AUTOSAR XML (schema 314)
package /VehicleProject
  system System: fibex-element=[CAN00, AFS_HS, AFS_HS__CAN00_Rx, AFS_HS__CAN00_Tx, AFS_Status_HS__CAN00, Antilock_Brake_and_TC_Status_HS__CAN00, Driven_Wheel_Grnd_Velocity_HS__CAN00, Driving_Mode_Control_HS__CAN00, DTC_Triggered_779__CAN00, NonDriven_Wheel_Grnd_Velocity_HS__CAN00, PPEI_Chassis_General_Status_1__CAN00, PPEI_Driven_Whl_Rotational_Stat__CAN00, PPEI_Engine_General_Status_1__CAN00, PPEI_Engine_General_Status_3__CAN00, PPEI_NonDrivn_Whl_Rotationl_Stat__CAN00, PPEI_Platform_General_Status__CAN00, PPEI_Trans_General_Status_2__CAN00, PPEI_VIN_Digits_10_to_17__CAN00, TsiCcpRx__CAN00, TsiCcpTx__CAN00, TsiDrvRxMsg__CAN00, TsiDrvTxMsg__CAN00, TsiTpRxMsg__CAN00, TsiTpTxMsg__CAN00, USDT_Req_to_AFS_HS__CAN00, USDT_Req_to_All_HS_ECUs__CAN00, USDT_Resp_From_AFS_HS__CAN00, UUDT_Resp_From_AFS_HS__CAN00, Vehicle_Odometer_HS__CAN00, VIN_Digits_2_to_9_HS__CAN00, Wheel_Pulses_HS__CAN00, AFS_Status_HS__CAN00, Antilock_Brake_and_TC_Status_HS__CAN00, Driven_Wheel_Grnd_Velocity_HS__CAN00, Driving_Mode_Control_HS__CAN00, DTC_Triggered_779__CAN00, NonDriven_Wheel_Grnd_Velocity_HS__CAN00, PPEI_Chassis_General_Status_1__CAN00, PPEI_Driven_Whl_Rotational_Stat__CAN00, PPEI_Engine_General_Status_1__CAN00, PPEI_Engine_General_Status_3__CAN00, PPEI_NonDrivn_Whl_Rotationl_Stat__CAN00, PPEI_Platform_General_Status__CAN00, PPEI_Trans_General_Status_2__CAN00, PPEI_VIN_Digits_10_to_17__CAN00, TsiCcpRx__CAN00, TsiCcpTx__CAN00, TsiDrvRxMsg__CAN00, TsiDrvTxMsg__CAN00, TsiTpRxMsg__CAN00, TsiTpTxMsg__CAN00, UUDT_Resp_From_AFS_HS__CAN00, Vehicle_Odometer_HS__CAN00, VIN_Digits_2_to_9_HS__CAN00, Wheel_Pulses_HS__CAN00, USDT_Req_to_AFS_HS__CAN00, USDT_Req_to_All_HS_ECUs__CAN00, USDT_Resp_From_AFS_HS__CAN00, USDT_Req_to_AFS_HS_Tp__CAN00, USDT_Req_to_All_HS_ECUs_Tp__CAN00, USDT_Resp_From_AFS_HS_Tp__CAN00, ABSAtv__PPEI_Chassis_General_Status_1__CAN00, ABSFld__PPEI_Chassis_General_Status_1__CAN00, AccActPos__PPEI_Engine_General_Status_1__CAN00, AccActPosV__PPEI_Engine_General_Status_1__CAN00, AFSIndOn__AFS_Status_HS__CAN00, AFSSysFail__AFS_Status_HS__CAN00, DrvMdCntrlState__Driving_Mode_Control_HS__CAN00, DTCI_CodeSupported_779__DTC_Triggered_779__CAN00, DTCI_CurrentStatus_779__DTC_Triggered_779__CAN00, DTCI_DTCFailType_779__DTC_Triggered_779__CAN00, DTCI_DTCFaultType_779__DTC_Triggered_779__CAN00, DTCI_DTCNumber_779__DTC_Triggered_779__CAN00, DTCI_DTCSource_779__DTC_Triggered_779__CAN00, DTCI_DTCTriggered_779__DTC_Triggered_779__CAN00, DTCI_HistStat_779__DTC_Triggered_779__CAN00, DTCI_TstFldCdClrdStat_779__DTC_Triggered_779__CAN00, DTCI_TstFldPwrUpSt_779__DTC_Triggered_779__CAN00, DTCI_TstNPsdCdClrdSt_779__DTC_Triggered_779__CAN00, DTCI_TstNPsdPwrUpSt_779__DTC_Triggered_779__CAN00, DTCI_WrnIndRqdSt_779__DTC_Triggered_779__CAN00, DTCIUnused1_779__DTC_Triggered_779__CAN00, DTCIUnused2_779__DTC_Triggered_779__CAN00, DTCIUnused3_779__DTC_Triggered_779__CAN00, DTCIUnused4_779__DTC_Triggered_779__CAN00, DTCIUnused5_779__DTC_Triggered_779__CAN00, DTCIUnused6_779__DTC_Triggered_779__CAN00, DTCIUnused7_779__DTC_Triggered_779__CAN00, EngRunAtv__PPEI_Engine_General_Status_1__CAN00, EngSpd__PPEI_Engine_General_Status_1__CAN00, FrStSysVeTpSpLimIndOn__AFS_Status_HS__CAN00, GenFld__PPEI_Engine_General_Status_3__CAN00, SG_DTCInfo_779__DTC_Triggered_779__CAN00, SG_WhlRotatStatLftDrvn__PPEI_Driven_Whl_Rotational_Stat__CAN00, SG_WhlRotatStatRtDrvn__PPEI_Driven_Whl_Rotational_Stat__CAN00, SG_WhlRotStatLftNDrvn__PPEI_NonDrivn_Whl_Rotationl_Stat__CAN00, SG_WhlRotStatRghtNDrvn__PPEI_NonDrivn_Whl_Rotationl_Stat__CAN00, SIRDpl__PPEI_Platform_General_Status__CAN00, StSysVehTopSpdLimReq__AFS_Status_HS__CAN00, SysBkUpPwrMd__PPEI_Platform_General_Status__CAN00, SysBkupPwrMdEn__PPEI_Platform_General_Status__CAN00, SysPwrMd__PPEI_Platform_General_Status__CAN00, TransEstGear__PPEI_Trans_General_Status_2__CAN00, TransEstGearV__PPEI_Trans_General_Status_2__CAN00, TrnsEngdState__PPEI_Trans_General_Status_2__CAN00, TrnsEngdStateV__PPEI_Trans_General_Status_2__CAN00, TrStLgMdAtv__PPEI_Platform_General_Status__CAN00, VehIdNmDig10_17__PPEI_VIN_Digits_10_to_17__CAN00, VehIdNmDig2_9__VIN_Digits_2_to_9_HS__CAN00, VehOdo__Vehicle_Odometer_HS__CAN00, VehOdoV__Vehicle_Odometer_HS__CAN00, VehStabEnhmntStat__Antilock_Brake_and_TC_Status_HS__CAN00, VhDynCntlSysSt__PPEI_Chassis_General_Status_1__CAN00, WhlGrndVlctyLftDrvn__Driven_Wheel_Grnd_Velocity_HS__CAN00, WhlGrndVlctyLftDrvnV__Driven_Wheel_Grnd_Velocity_HS__CAN00, WhlGrndVlctyLftNnDrvn__NonDriven_Wheel_Grnd_Velocity_HS__CAN00, WhlGrndVlctyLftNnDrvnV__NonDriven_Wheel_Grnd_Velocity_HS__CAN00, WhlGrndVlctyRtDrvn__Driven_Wheel_Grnd_Velocity_HS__CAN00, WhlGrndVlctyRtDrvnV__Driven_Wheel_Grnd_Velocity_HS__CAN00, WhlGrndVlctyRtNnDrvn__NonDriven_Wheel_Grnd_Velocity_HS__CAN00, WhlGrndVlctyRtNnDrvnV__NonDriven_Wheel_Grnd_Velocity_HS__CAN00, WhlPlsPerRevDrvn__Wheel_Pulses_HS__CAN00, WhlPlsPerRevNonDrvn__Wheel_Pulses_HS__CAN00, WRSLDSeqNum__PPEI_Driven_Whl_Rotational_Stat__CAN00, WRSLDWhlDistPlsCntr__PPEI_Driven_Whl_Rotational_Stat__CAN00, WRSLDWhlDisTpRC__PPEI_Driven_Whl_Rotational_Stat__CAN00, WRSLDWhlDistTmstm__PPEI_Driven_Whl_Rotational_Stat__CAN00, WRSLDWhlDistVal__PPEI_Driven_Whl_Rotational_Stat__CAN00, WRSLDWhlRotStatRst__PPEI_Driven_Whl_Rotational_Stat__CAN00, WRSLNDSeqNum__PPEI_NonDrivn_Whl_Rotationl_Stat__CAN00, WRSLNDWhlDistPCntr__PPEI_NonDrivn_Whl_Rotationl_Stat__CAN00, WRSLNDWhlDisTpRC__PPEI_NonDrivn_Whl_Rotationl_Stat__CAN00, WRSLNDWhlDistTstm__PPEI_NonDrivn_Whl_Rotationl_Stat__CAN00, WRSLNDWhlDistVal__PPEI_NonDrivn_Whl_Rotationl_Stat__CAN00, WRSLNDWhlRotStRst__PPEI_NonDrivn_Whl_Rotationl_Stat__CAN00, WRSRDSeqNum__PPEI_Driven_Whl_Rotational_Stat__CAN00, WRSRDWhlDistPlsCntr__PPEI_Driven_Whl_Rotational_Stat__CAN00, WRSRDWhlDisTpRC__PPEI_Driven_Whl_Rotational_Stat__CAN00, WRSRDWhlDistTmstm__PPEI_Driven_Whl_Rotational_Stat__CAN00, WRSRDWhlDistVal__PPEI_Driven_Whl_Rotational_Stat__CAN00, WRSRDWhlRotStatRst__PPEI_Driven_Whl_Rotational_Stat__CAN00, WRSRNDSeqNum__PPEI_NonDrivn_Whl_Rotationl_Stat__CAN00, WRSRNDWhlDistPCntr__PPEI_NonDrivn_Whl_Rotationl_Stat__CAN00, WRSRNDWhlDisTpRC__PPEI_NonDrivn_Whl_Rotationl_Stat__CAN00, WRSRNDWhlDistTstm__PPEI_NonDrivn_Whl_Rotationl_Stat__CAN00, WRSRNDWhlDistVal__PPEI_NonDrivn_Whl_Rotationl_Stat__CAN00, WRSRNDWhlRotStRst__PPEI_NonDrivn_Whl_Rotationl_Stat__CAN00]
package /Cluster
  can cluster CAN00: protocol-name=CAN, nm-lower-can-id=1536, nm-upper-can-id=1551  # gmHS | Primary High Speed GMLAN
    physical channel CHNL
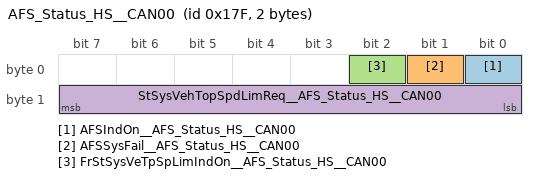
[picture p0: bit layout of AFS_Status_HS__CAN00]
      frame AFS_Status_HS__CAN00: id 0x17F, from AFS_HS, frame-length=2, can-addressing-mode=STANDARD
        pdu AFS_Status_HS__CAN00: length=16, cyclic-timing={repeating-time=0.1, starting-time=0}, minimum-delay=0, transmission-mode-false-timing=cyclic-timing={repeating-time=0.1, starting-time=0}
          signal AFSIndOn__AFS_Status_HS__CAN00: start 0, 1 bit, big-endian, data-type=DT_AFSIndOn, init-value=C_AFSIndOn, transfer-property=PENDING
          signal AFSSysFail__AFS_Status_HS__CAN00: start 1, 1 bit, big-endian, data-type=DT_AFSSysFail, init-value=C_AFSSysFail, transfer-property=PENDING
          signal FrStSysVeTpSpLimIndOn__AFS_Status_HS__CAN00: start 2, 1 bit, big-endian, data-type=DT_FrStSysVeTpSpLimIndOn, init-value=C_FrStSysVeTpSpLimIndOn, transfer-property=PENDING
          signal StSysVehTopSpdLimReq__AFS_Status_HS__CAN00: start 15, 8 bit, big-endian, data-type=DT_StSysVehTopSpdLimReq, init-value=C_StSysVehTopSpdLimReq, transfer-property=PENDING
      frame Antilock_Brake_and_TC_Status_HS__CAN00: id 0x17D, to AFS_HS, frame-length=6, can-addressing-mode=STANDARD
        pdu Antilock_Brake_and_TC_Status_HS__CAN00: length=48, cyclic-timing={repeating-time=0.1, starting-time=0}, minimum-delay=0, transmission-mode-false-timing=cyclic-timing={repeating-time=0.1, starting-time=0}
          signal VehStabEnhmntStat__Antilock_Brake_and_TC_Status_HS__CAN00: start 4, 3 bit, big-endian, data-type=DT_VehStabEnhmntStat, init-value=C_VehStabEnhmntStat, transfer-property=PENDING, to AFS_HS
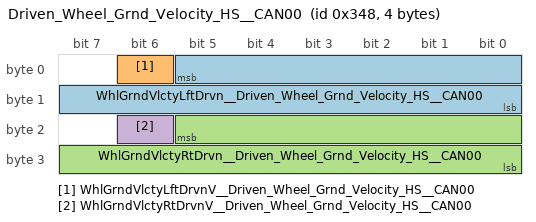
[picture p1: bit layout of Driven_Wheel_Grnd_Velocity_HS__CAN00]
      frame Driven_Wheel_Grnd_Velocity_HS__CAN00: id 0x348, to AFS_HS, frame-length=4, can-addressing-mode=STANDARD
        pdu Driven_Wheel_Grnd_Velocity_HS__CAN00: length=32, cyclic-timing={repeating-time=0.05, starting-time=0}, minimum-delay=0, transmission-mode-false-timing=cyclic-timing={repeating-time=0.05, starting-time=0}
          signal WhlGrndVlctyLftDrvn__Driven_Wheel_Grnd_Velocity_HS__CAN00: start 5, 14 bit, big-endian, data-type=DT_WhlGrndVlctyLftDrvn, init-value=C_WhlGrndVlctyLftDrvn, transfer-property=PENDING, to AFS_HS
          signal WhlGrndVlctyLftDrvnV__Driven_Wheel_Grnd_Velocity_HS__CAN00: start 6, 1 bit, big-endian, data-type=DT_WhlGrndVlctyLftDrvnV, init-value=C_WhlGrndVlctyLftDrvnV, transfer-property=PENDING, to AFS_HS
          signal WhlGrndVlctyRtDrvn__Driven_Wheel_Grnd_Velocity_HS__CAN00: start 21, 14 bit, big-endian, data-type=DT_WhlGrndVlctyRtDrvn, init-value=C_WhlGrndVlctyRtDrvn, transfer-property=PENDING, to AFS_HS
          signal WhlGrndVlctyRtDrvnV__Driven_Wheel_Grnd_Velocity_HS__CAN00: start 22, 1 bit, big-endian, data-type=DT_WhlGrndVlctyRtDrvnV, init-value=C_WhlGrndVlctyRtDrvnV, transfer-property=PENDING, to AFS_HS
      frame Driving_Mode_Control_HS__CAN00: id 0x232, to AFS_HS, frame-length=7, can-addressing-mode=STANDARD
        pdu Driving_Mode_Control_HS__CAN00: length=56, cyclic-timing={repeating-time=0.02, starting-time=0}, minimum-delay=0, transmission-mode-false-timing=cyclic-timing={repeating-time=0.02, starting-time=0}
          signal DrvMdCntrlState__Driving_Mode_Control_HS__CAN00: start 39, 8 bit, big-endian, data-type=DT_DrvMdCntrlState, init-value=C_DrvMdCntrlState, transfer-property=PENDING, to AFS_HS
      frame DTC_Triggered_779__CAN00: id 0x779, from AFS_HS, frame-length=7, can-addressing-mode=STANDARD
        pdu DTC_Triggered_779__CAN00: length=56, cyclic-timing={repeating-time=1, starting-time=0}, minimum-delay=0, transmission-mode-false-timing=cyclic-timing={repeating-time=1, starting-time=0}
          signal DTCI_DTCTriggered_779__DTC_Triggered_779__CAN00: start 0, 1 bit, big-endian, data-type=DT_DTCI_DTCTriggered_779, init-value=C_DTCI_DTCTriggered_779, transfer-property=PENDING
          signal DTCIUnused7_779__DTC_Triggered_779__CAN00: start 1, 1 bit, big-endian, data-type=DT_DTCIUnused7_779, init-value=C_DTCIUnused7_779, transfer-property=PENDING
          signal DTCIUnused6_779__DTC_Triggered_779__CAN00: start 2, 1 bit, big-endian, data-type=DT_DTCIUnused6_779, init-value=C_DTCIUnused6_779, transfer-property=PENDING
          signal DTCIUnused5_779__DTC_Triggered_779__CAN00: start 3, 1 bit, big-endian, data-type=DT_DTCIUnused5_779, init-value=C_DTCIUnused5_779, transfer-property=PENDING
          signal DTCIUnused4_779__DTC_Triggered_779__CAN00: start 4, 1 bit, big-endian, data-type=DT_DTCIUnused4_779, init-value=C_DTCIUnused4_779, transfer-property=PENDING
          signal DTCIUnused3_779__DTC_Triggered_779__CAN00: start 5, 1 bit, big-endian, data-type=DT_DTCIUnused3_779, init-value=C_DTCIUnused3_779, transfer-property=PENDING
          signal DTCIUnused2_779__DTC_Triggered_779__CAN00: start 6, 1 bit, big-endian, data-type=DT_DTCIUnused2_779, init-value=C_DTCIUnused2_779, transfer-property=PENDING
          signal DTCIUnused1_779__DTC_Triggered_779__CAN00: start 7, 1 bit, big-endian, data-type=DT_DTCIUnused1_779, init-value=C_DTCIUnused1_779, transfer-property=PENDING
          signal DTCI_DTCSource_779__DTC_Triggered_779__CAN00: start 15, 8 bit, big-endian, data-type=DT_DTCI_DTCSource_779, init-value=C_DTCI_DTCSource_779, transfer-property=PENDING  # This shall be equal to the Diagnostic Address of the transmittting device.
          signal DTCI_DTCNumber_779__DTC_Triggered_779__CAN00: start 23, 16 bit, big-endian, data-type=DT_DTCI_DTCNumber_779, init-value=C_DTCI_DTCNumber_779, transfer-property=PENDING
          signal DTCI_DTCFailType_779__DTC_Triggered_779__CAN00: start 39, 8 bit, big-endian, data-type=DT_DTCI_DTCFailType_779, init-value=C_DTCI_DTCFailType_779, transfer-property=PENDING  # Assigned per GMW3110, Appendix E
          signal DTCI_CodeSupported_779__DTC_Triggered_779__CAN00: start 40, 1 bit, big-endian, data-type=DT_DTCI_CodeSupported_779, init-value=C_DTCI_CodeSupported_779, transfer-property=PENDING
          signal DTCI_CurrentStatus_779__DTC_Triggered_779__CAN00: start 41, 1 bit, big-endian, data-type=DT_DTCI_CurrentStatus_779, init-value=C_DTCI_CurrentStatus_779, transfer-property=PENDING
          signal DTCI_TstNPsdCdClrdSt_779__DTC_Triggered_779__CAN00: start 42, 1 bit, big-endian, data-type=DT_DTCI_TstNPsdCdClrdSt_779, init-value=C_DTCI_TstNPsdCdClrdSt_779, transfer-property=PENDING
          signal DTCI_TstFldCdClrdStat_779__DTC_Triggered_779__CAN00: start 43, 1 bit, big-endian, data-type=DT_DTCI_TstFldCdClrdStat_779, init-value=C_DTCI_TstFldCdClrdStat_779, transfer-property=PENDING
          signal DTCI_HistStat_779__DTC_Triggered_779__CAN00: start 44, 1 bit, big-endian, data-type=DT_DTCI_HistStat_779, init-value=C_DTCI_HistStat_779, transfer-property=PENDING
          signal DTCI_TstNPsdPwrUpSt_779__DTC_Triggered_779__CAN00: start 45, 1 bit, big-endian, data-type=DT_DTCI_TstNPsdPwrUpSt_779, init-value=C_DTCI_TstNPsdPwrUpSt_779, transfer-property=PENDING
          signal DTCI_TstFldPwrUpSt_779__DTC_Triggered_779__CAN00: start 46, 1 bit, big-endian, data-type=DT_DTCI_TstFldPwrUpSt_779, init-value=C_DTCI_TstFldPwrUpSt_779, transfer-property=PENDING
          signal DTCI_WrnIndRqdSt_779__DTC_Triggered_779__CAN00: start 47, 1 bit, big-endian, data-type=DT_DTCI_WrnIndRqdSt_779, init-value=C_DTCI_WrnIndRqdSt_779, transfer-property=PENDING
          signal DTCI_DTCFaultType_779__DTC_Triggered_779__CAN00: start 55, 8 bit, big-endian, data-type=DT_DTCI_DTCFaultType_779, init-value=C_DTCI_DTCFaultType_779, transfer-property=PENDING  # Based on Powertrain definition. Not expected to be supported by all devices.
          signal SG_DTCInfo_779__DTC_Triggered_779__CAN00: start 7, big-endian, system-signal=[DTCI_CodeSupported_779, DTCI_CurrentStatus_779, DTCI_DTCFailType_779, DTCI_DTCFaultType_779, DTCI_DTCNumber_779, DTCI_DTCSource_779, DTCI_DTCTriggered_779, DTCI_HistStat_779, DTCI_TstFldCdClrdStat_779, DTCI_TstFldPwrUpSt_779, DTCI_TstNPsdCdClrdSt_779, DTCI_TstNPsdPwrUpSt_779, DTCI_WrnIndRqdSt_779, DTCIUnused1_779, DTCIUnused2_779, DTCIUnused3_779, DTCIUnused4_779, DTCIUnused5_779, DTCIUnused6_779, DTCIUnused7_779], transfer-property=PENDING
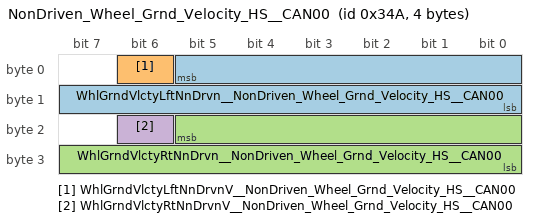
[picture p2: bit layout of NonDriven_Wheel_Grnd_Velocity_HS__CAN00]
      frame NonDriven_Wheel_Grnd_Velocity_HS__CAN00: id 0x34A, to AFS_HS, frame-length=4, can-addressing-mode=STANDARD
        pdu NonDriven_Wheel_Grnd_Velocity_HS__CAN00: length=32, cyclic-timing={repeating-time=0.05, starting-time=0}, minimum-delay=0, transmission-mode-false-timing=cyclic-timing={repeating-time=0.05, starting-time=0}
          signal WhlGrndVlctyLftNnDrvn__NonDriven_Wheel_Grnd_Velocity_HS__CAN00: start 5, 14 bit, big-endian, data-type=DT_WhlGrndVlctyLftNnDrvn, init-value=C_WhlGrndVlctyLftNnDrvn, transfer-property=PENDING, to AFS_HS
          signal WhlGrndVlctyLftNnDrvnV__NonDriven_Wheel_Grnd_Velocity_HS__CAN00: start 6, 1 bit, big-endian, data-type=DT_WhlGrndVlctyLftNnDrvnV, init-value=C_WhlGrndVlctyLftNnDrvnV, transfer-property=PENDING, to AFS_HS
          signal WhlGrndVlctyRtNnDrvn__NonDriven_Wheel_Grnd_Velocity_HS__CAN00: start 21, 14 bit, big-endian, data-type=DT_WhlGrndVlctyRtNnDrvn, init-value=C_WhlGrndVlctyRtNnDrvn, transfer-property=PENDING, to AFS_HS
          signal WhlGrndVlctyRtNnDrvnV__NonDriven_Wheel_Grnd_Velocity_HS__CAN00: start 22, 1 bit, big-endian, data-type=DT_WhlGrndVlctyRtNnDrvnV, init-value=C_WhlGrndVlctyRtNnDrvnV, transfer-property=PENDING, to AFS_HS
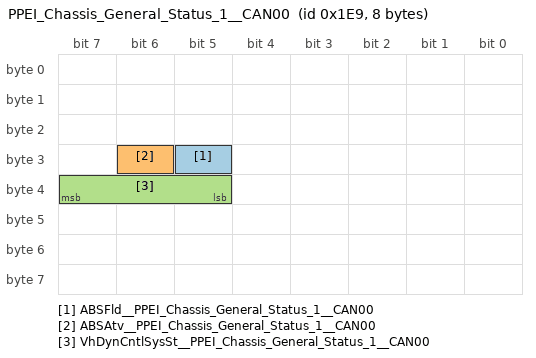
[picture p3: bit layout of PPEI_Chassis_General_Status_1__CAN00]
      frame PPEI_Chassis_General_Status_1__CAN00: id 0x1E9, to AFS_HS, frame-length=8, can-addressing-mode=STANDARD  # Changed for PPEI 3.6
        pdu PPEI_Chassis_General_Status_1__CAN00: length=64, cyclic-timing={repeating-time=0.02, starting-time=0}, minimum-delay=0, transmission-mode-false-timing=cyclic-timing={repeating-time=0.02, starting-time=0}
          signal ABSFld__PPEI_Chassis_General_Status_1__CAN00: start 29, 1 bit, big-endian, data-type=DT_ABSFld, init-value=C_ABSFld, transfer-property=PENDING, to AFS_HS
          signal ABSAtv__PPEI_Chassis_General_Status_1__CAN00: start 30, 1 bit, big-endian, data-type=DT_ABSAtv, init-value=C_ABSAtv, transfer-property=PENDING, to AFS_HS
          signal VhDynCntlSysSt__PPEI_Chassis_General_Status_1__CAN00: start 39, 3 bit, big-endian, data-type=DT_VhDynCntlSysSt, init-value=C_VhDynCntlSysSt, transfer-property=PENDING, to AFS_HS
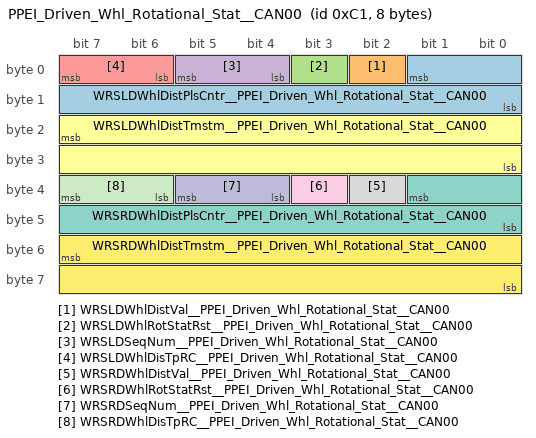
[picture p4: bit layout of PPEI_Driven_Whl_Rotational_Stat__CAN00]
      frame PPEI_Driven_Whl_Rotational_Stat__CAN00: id 0xC1, to AFS_HS, frame-length=8, can-addressing-mode=STANDARD
        pdu PPEI_Driven_Whl_Rotational_Stat__CAN00: length=64, cyclic-timing={repeating-time=0.01, starting-time=0}, minimum-delay=0, transmission-mode-false-timing=cyclic-timing={repeating-time=0.01, starting-time=0}
          signal WRSLDWhlDistPlsCntr__PPEI_Driven_Whl_Rotational_Stat__CAN00: start 1, 10 bit, big-endian, data-type=DT_WRSLDWhlDistPlsCntr, init-value=C_WRSLDWhlDistPlsCntr, transfer-property=PENDING, to AFS_HS
          signal WRSLDWhlDistVal__PPEI_Driven_Whl_Rotational_Stat__CAN00: start 2, 1 bit, big-endian, data-type=DT_WRSLDWhlDistVal, init-value=C_WRSLDWhlDistVal, transfer-property=PENDING, to AFS_HS
          signal WRSLDWhlRotStatRst__PPEI_Driven_Whl_Rotational_Stat__CAN00: start 3, 1 bit, big-endian, data-type=DT_WRSLDWhlRotStatRst, init-value=C_WRSLDWhlRotStatRst, transfer-property=PENDING, to AFS_HS
          signal WRSLDSeqNum__PPEI_Driven_Whl_Rotational_Stat__CAN00: start 5, 2 bit, big-endian, data-type=DT_WRSLDSeqNum, init-value=C_WRSLDSeqNum, transfer-property=PENDING, to AFS_HS
          signal WRSLDWhlDisTpRC__PPEI_Driven_Whl_Rotational_Stat__CAN00: start 7, 2 bit, big-endian, data-type=DT_WRSLDWhlDisTpRC, init-value=C_WRSLDWhlDisTpRC, transfer-property=PENDING, to AFS_HS
          signal WRSLDWhlDistTmstm__PPEI_Driven_Whl_Rotational_Stat__CAN00: start 23, 16 bit, big-endian, data-type=DT_WRSLDWhlDistTmstm, init-value=C_WRSLDWhlDistTmstm, transfer-property=PENDING, to AFS_HS
          signal WRSRDWhlDistPlsCntr__PPEI_Driven_Whl_Rotational_Stat__CAN00: start 33, 10 bit, big-endian, data-type=DT_WRSRDWhlDistPlsCntr, init-value=C_WRSRDWhlDistPlsCntr, transfer-property=PENDING, to AFS_HS
          signal WRSRDWhlDistVal__PPEI_Driven_Whl_Rotational_Stat__CAN00: start 34, 1 bit, big-endian, data-type=DT_WRSRDWhlDistVal, init-value=C_WRSRDWhlDistVal, transfer-property=PENDING, to AFS_HS
          signal WRSRDWhlRotStatRst__PPEI_Driven_Whl_Rotational_Stat__CAN00: start 35, 1 bit, big-endian, data-type=DT_WRSRDWhlRotStatRst, init-value=C_WRSRDWhlRotStatRst, transfer-property=PENDING, to AFS_HS
          signal WRSRDSeqNum__PPEI_Driven_Whl_Rotational_Stat__CAN00: start 37, 2 bit, big-endian, data-type=DT_WRSRDSeqNum, init-value=C_WRSRDSeqNum, transfer-property=PENDING, to AFS_HS
          signal WRSRDWhlDisTpRC__PPEI_Driven_Whl_Rotational_Stat__CAN00: start 39, 2 bit, big-endian, data-type=DT_WRSRDWhlDisTpRC, init-value=C_WRSRDWhlDisTpRC, transfer-property=PENDING, to AFS_HS
          signal WRSRDWhlDistTmstm__PPEI_Driven_Whl_Rotational_Stat__CAN00: start 55, 16 bit, big-endian, data-type=DT_WRSRDWhlDistTmstm, init-value=C_WRSRDWhlDistTmstm, transfer-property=PENDING, to AFS_HS
          signal SG_WhlRotatStatLftDrvn__PPEI_Driven_Whl_Rotational_Stat__CAN00: start 7, big-endian, system-signal=[WRSLDSeqNum, WRSLDWhlDistPlsCntr, WRSLDWhlDisTpRC, WRSLDWhlDistTmstm, WRSLDWhlDistVal, WRSLDWhlRotStatRst], transfer-property=PENDING
          signal SG_WhlRotatStatRtDrvn__PPEI_Driven_Whl_Rotational_Stat__CAN00: start 39, big-endian, system-signal=[WRSRDSeqNum, WRSRDWhlDistPlsCntr, WRSRDWhlDisTpRC, WRSRDWhlDistTmstm, WRSRDWhlDistVal, WRSRDWhlRotStatRst], transfer-property=PENDING
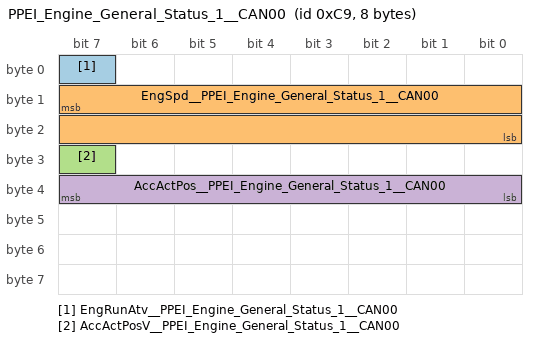
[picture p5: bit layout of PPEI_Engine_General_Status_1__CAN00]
      frame PPEI_Engine_General_Status_1__CAN00: id 0xC9, to AFS_HS, frame-length=8, can-addressing-mode=STANDARD  # Changed for PPEI 3.6
        pdu PPEI_Engine_General_Status_1__CAN00: length=64, cyclic-timing={repeating-time=0.012, starting-time=0}, minimum-delay=0, transmission-mode-false-timing=cyclic-timing={repeating-time=0.012, starting-time=0}
          signal EngRunAtv__PPEI_Engine_General_Status_1__CAN00: start 7, 1 bit, big-endian, data-type=DT_EngRunAtv, init-value=C_EngRunAtv, transfer-property=PENDING, to AFS_HS  # Indication from powertrain that the engine is running (Has RPM > 0)
          signal EngSpd__PPEI_Engine_General_Status_1__CAN00: start 15, 16 bit, big-endian, data-type=DT_EngSpd, init-value=C_EngSpd, transfer-property=PENDING, to AFS_HS
          signal AccActPosV__PPEI_Engine_General_Status_1__CAN00: start 31, 1 bit, big-endian, data-type=DT_AccActPosV, init-value=C_AccActPosV, transfer-property=PENDING, to AFS_HS
          signal AccActPos__PPEI_Engine_General_Status_1__CAN00: start 39, 8 bit, big-endian, data-type=DT_AccActPos, init-value=C_AccActPos, transfer-property=PENDING, to AFS_HS
      frame PPEI_Engine_General_Status_3__CAN00: id 0x3F9, to AFS_HS, frame-length=8, can-addressing-mode=STANDARD
        pdu PPEI_Engine_General_Status_3__CAN00: length=64, cyclic-timing={repeating-time=0.25, starting-time=0}, minimum-delay=0, transmission-mode-false-timing=cyclic-timing={repeating-time=0.25, starting-time=0}
          signal GenFld__PPEI_Engine_General_Status_3__CAN00: start 5, 1 bit, big-endian, data-type=DT_GenFld, init-value=C_GenFld, transfer-property=PENDING, to AFS_HS
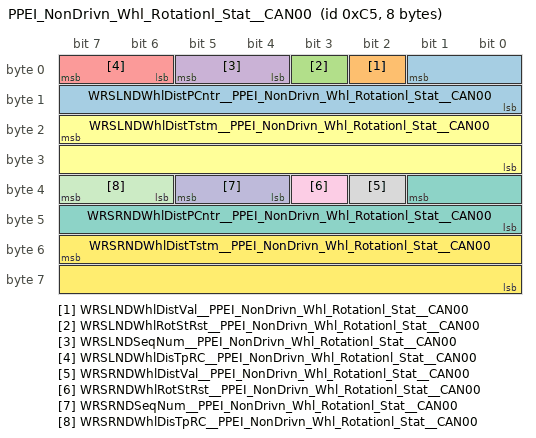
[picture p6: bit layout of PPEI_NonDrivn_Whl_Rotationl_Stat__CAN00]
      frame PPEI_NonDrivn_Whl_Rotationl_Stat__CAN00: id 0xC5, to AFS_HS, frame-length=8, can-addressing-mode=STANDARD
        pdu PPEI_NonDrivn_Whl_Rotationl_Stat__CAN00: length=64, cyclic-timing={repeating-time=0.01, starting-time=0}, minimum-delay=0, transmission-mode-false-timing=cyclic-timing={repeating-time=0.01, starting-time=0}
          signal WRSLNDWhlDistPCntr__PPEI_NonDrivn_Whl_Rotationl_Stat__CAN00: start 1, 10 bit, big-endian, data-type=DT_WRSLNDWhlDistPCntr, init-value=C_WRSLNDWhlDistPCntr, transfer-property=PENDING, to AFS_HS
          signal WRSLNDWhlDistVal__PPEI_NonDrivn_Whl_Rotationl_Stat__CAN00: start 2, 1 bit, big-endian, data-type=DT_WRSLNDWhlDistVal, init-value=C_WRSLNDWhlDistVal, transfer-property=PENDING, to AFS_HS
          signal WRSLNDWhlRotStRst__PPEI_NonDrivn_Whl_Rotationl_Stat__CAN00: start 3, 1 bit, big-endian, data-type=DT_WRSLNDWhlRotStRst, init-value=C_WRSLNDWhlRotStRst, transfer-property=PENDING, to AFS_HS
          signal WRSLNDSeqNum__PPEI_NonDrivn_Whl_Rotationl_Stat__CAN00: start 5, 2 bit, big-endian, data-type=DT_WRSLNDSeqNum, init-value=C_WRSLNDSeqNum, transfer-property=PENDING, to AFS_HS
          signal WRSLNDWhlDisTpRC__PPEI_NonDrivn_Whl_Rotationl_Stat__CAN00: start 7, 2 bit, big-endian, data-type=DT_WRSLNDWhlDisTpRC, init-value=C_WRSLNDWhlDisTpRC, transfer-property=PENDING, to AFS_HS
          signal WRSLNDWhlDistTstm__PPEI_NonDrivn_Whl_Rotationl_Stat__CAN00: start 23, 16 bit, big-endian, data-type=DT_WRSLNDWhlDistTstm, init-value=C_WRSLNDWhlDistTstm, transfer-property=PENDING, to AFS_HS
          signal WRSRNDWhlDistPCntr__PPEI_NonDrivn_Whl_Rotationl_Stat__CAN00: start 33, 10 bit, big-endian, data-type=DT_WRSRNDWhlDistPCntr, init-value=C_WRSRNDWhlDistPCntr, transfer-property=PENDING, to AFS_HS
          signal WRSRNDWhlDistVal__PPEI_NonDrivn_Whl_Rotationl_Stat__CAN00: start 34, 1 bit, big-endian, data-type=DT_WRSRNDWhlDistVal, init-value=C_WRSRNDWhlDistVal, transfer-property=PENDING, to AFS_HS
          signal WRSRNDWhlRotStRst__PPEI_NonDrivn_Whl_Rotationl_Stat__CAN00: start 35, 1 bit, big-endian, data-type=DT_WRSRNDWhlRotStRst, init-value=C_WRSRNDWhlRotStRst, transfer-property=PENDING, to AFS_HS
          signal WRSRNDSeqNum__PPEI_NonDrivn_Whl_Rotationl_Stat__CAN00: start 37, 2 bit, big-endian, data-type=DT_WRSRNDSeqNum, init-value=C_WRSRNDSeqNum, transfer-property=PENDING, to AFS_HS
          signal WRSRNDWhlDisTpRC__PPEI_NonDrivn_Whl_Rotationl_Stat__CAN00: start 39, 2 bit, big-endian, data-type=DT_WRSRNDWhlDisTpRC, init-value=C_WRSRNDWhlDisTpRC, transfer-property=PENDING, to AFS_HS
          signal WRSRNDWhlDistTstm__PPEI_NonDrivn_Whl_Rotationl_Stat__CAN00: start 55, 16 bit, big-endian, data-type=DT_WRSRNDWhlDistTstm, init-value=C_WRSRNDWhlDistTstm, transfer-property=PENDING, to AFS_HS
          signal SG_WhlRotStatLftNDrvn__PPEI_NonDrivn_Whl_Rotationl_Stat__CAN00: start 7, big-endian, system-signal=[WRSLNDSeqNum, WRSLNDWhlDistPCntr, WRSLNDWhlDisTpRC, WRSLNDWhlDistTstm, WRSLNDWhlDistVal, WRSLNDWhlRotStRst], transfer-property=PENDING
          signal SG_WhlRotStatRghtNDrvn__PPEI_NonDrivn_Whl_Rotationl_Stat__CAN00: start 39, big-endian, system-signal=[WRSRNDSeqNum, WRSRNDWhlDistPCntr, WRSRNDWhlDisTpRC, WRSRNDWhlDistTstm, WRSRNDWhlDistVal, WRSRNDWhlRotStRst], transfer-property=PENDING
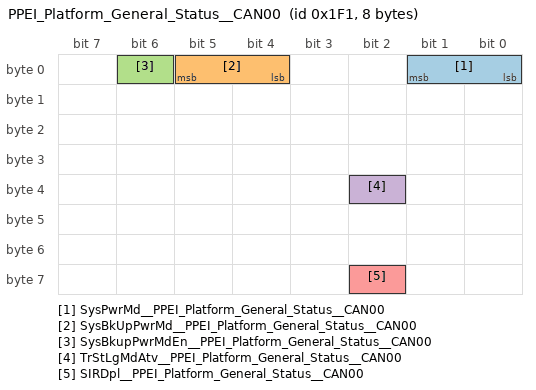
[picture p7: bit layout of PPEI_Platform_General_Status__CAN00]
      frame PPEI_Platform_General_Status__CAN00: id 0x1F1, to AFS_HS, frame-length=8, can-addressing-mode=STANDARD
        pdu PPEI_Platform_General_Status__CAN00: length=64, cyclic-timing={repeating-time=0.1, starting-time=0}, minimum-delay=0.03, transmission-mode-false-timing=cyclic-timing={repeating-time=0.1, starting-time=0}
          signal SysPwrMd__PPEI_Platform_General_Status__CAN00: start 1, 2 bit, big-endian, data-type=DT_SysPwrMd, init-value=C_SysPwrMd, transfer-property=PENDING, to AFS_HS
          signal SysBkUpPwrMd__PPEI_Platform_General_Status__CAN00: start 5, 2 bit, big-endian, data-type=DT_SysBkUpPwrMd, init-value=C_SysBkUpPwrMd, transfer-property=PENDING, to AFS_HS
          signal SysBkupPwrMdEn__PPEI_Platform_General_Status__CAN00: start 6, 1 bit, big-endian, data-type=DT_SysBkupPwrMdEn, init-value=C_SysBkupPwrMdEn, transfer-property=PENDING, to AFS_HS
          signal TrStLgMdAtv__PPEI_Platform_General_Status__CAN00: start 34, 1 bit, big-endian, data-type=DT_TrStLgMdAtv, init-value=C_TrStLgMdAtv, transfer-property=PENDING, to AFS_HS
          signal SIRDpl__PPEI_Platform_General_Status__CAN00: start 58, 1 bit, big-endian, data-type=DT_SIRDpl, init-value=C_SIRDpl, transfer-property=PENDING, to AFS_HS
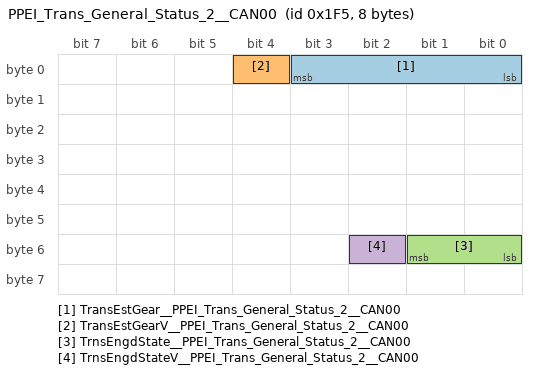
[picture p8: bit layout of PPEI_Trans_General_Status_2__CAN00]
      frame PPEI_Trans_General_Status_2__CAN00: id 0x1F5, to AFS_HS, frame-length=8, can-addressing-mode=STANDARD
        pdu PPEI_Trans_General_Status_2__CAN00: length=64, cyclic-timing={repeating-time=0.025, starting-time=0}, minimum-delay=0, transmission-mode-false-timing=cyclic-timing={repeating-time=0.025, starting-time=0}
          signal TransEstGear__PPEI_Trans_General_Status_2__CAN00: start 3, 4 bit, big-endian, data-type=DT_TransEstGear, init-value=C_TransEstGear, transfer-property=PENDING, to AFS_HS
          signal TransEstGearV__PPEI_Trans_General_Status_2__CAN00: start 4, 1 bit, big-endian, data-type=DT_TransEstGearV, init-value=C_TransEstGearV, transfer-property=PENDING, to AFS_HS
          signal TrnsEngdState__PPEI_Trans_General_Status_2__CAN00: start 49, 2 bit, big-endian, data-type=DT_TrnsEngdState, init-value=C_TrnsEngdState, transfer-property=PENDING, to AFS_HS
          signal TrnsEngdStateV__PPEI_Trans_General_Status_2__CAN00: start 50, 1 bit, big-endian, data-type=DT_TrnsEngdStateV, init-value=C_TrnsEngdStateV, transfer-property=PENDING, to AFS_HS
      frame PPEI_VIN_Digits_10_to_17__CAN00: id 0x4E1, to AFS_HS, frame-length=8, can-addressing-mode=STANDARD
        pdu PPEI_VIN_Digits_10_to_17__CAN00: length=64, cyclic-timing={repeating-time=1, starting-time=0}, minimum-delay=0, transmission-mode-false-timing=cyclic-timing={repeating-time=1, starting-time=0}
          signal VehIdNmDig10_17__PPEI_VIN_Digits_10_to_17__CAN00: start 7, 64 bit, big-endian, data-type=DT_VehIdNmDig10_17, init-value=C_VehIdNmDig10_17, transfer-property=PENDING, to AFS_HS  # Desc: 8 ASCII Characters
      frame TsiCcpRx__CAN00: id 0x791, to AFS_HS, frame-length=8, can-addressing-mode=STANDARD
        pdu TsiCcpRx__CAN00: length=64
      frame TsiCcpTx__CAN00: id 0x790, from AFS_HS, frame-length=8, can-addressing-mode=STANDARD
        pdu TsiCcpTx__CAN00: length=64
      frame TsiDrvRxMsg__CAN00: id 0x793, to AFS_HS, frame-length=8, can-addressing-mode=STANDARD
        pdu TsiDrvRxMsg__CAN00: length=64
      frame TsiDrvTxMsg__CAN00: id 0x792, from AFS_HS, frame-length=8, can-addressing-mode=STANDARD
        pdu TsiDrvTxMsg__CAN00: length=64
      frame TsiTpRxMsg__CAN00: id 0x795, to AFS_HS, frame-length=8, can-addressing-mode=STANDARD
        pdu TsiTpRxMsg__CAN00: length=64
      frame TsiTpTxMsg__CAN00: id 0x794, from AFS_HS, frame-length=8, can-addressing-mode=STANDARD
        pdu TsiTpTxMsg__CAN00: length=64
      frame USDT_Req_to_AFS_HS__CAN00: id 0x255, to AFS_HS, frame-length=8, can-addressing-mode=STANDARD
        n pdu USDT_Req_to_AFS_HS_Tp__CAN00: length=64
      frame USDT_Req_to_All_HS_ECUs__CAN00: id 0x101, to AFS_HS, frame-length=8, can-addressing-mode=STANDARD
        n pdu USDT_Req_to_All_HS_ECUs_Tp__CAN00: length=64
      frame USDT_Resp_From_AFS_HS__CAN00: id 0x655, from AFS_HS, frame-length=8, can-addressing-mode=STANDARD
        n pdu USDT_Resp_From_AFS_HS_Tp__CAN00: length=64
      frame UUDT_Resp_From_AFS_HS__CAN00: id 0x555, from AFS_HS, frame-length=8, can-addressing-mode=STANDARD
        pdu UUDT_Resp_From_AFS_HS__CAN00: length=64
      frame Vehicle_Odometer_HS__CAN00: id 0x120, to AFS_HS, frame-length=5, can-addressing-mode=STANDARD
        pdu Vehicle_Odometer_HS__CAN00: length=40, cyclic-timing={repeating-time=5, starting-time=0}, minimum-delay=0, transmission-mode-false-timing=cyclic-timing={repeating-time=5, starting-time=0}
          signal VehOdo__Vehicle_Odometer_HS__CAN00: start 7, 32 bit, big-endian, data-type=DT_VehOdo, init-value=C_VehOdo, transfer-property=PENDING, to AFS_HS
          signal VehOdoV__Vehicle_Odometer_HS__CAN00: start 32, 1 bit, big-endian, data-type=DT_VehOdoV, init-value=C_VehOdoV, transfer-property=PENDING, to AFS_HS
      frame VIN_Digits_2_to_9_HS__CAN00: id 0x514, to AFS_HS, frame-length=8, can-addressing-mode=STANDARD
        pdu VIN_Digits_2_to_9_HS__CAN00: length=64, cyclic-timing={repeating-time=1, starting-time=0}, minimum-delay=0, transmission-mode-false-timing=cyclic-timing={repeating-time=1, starting-time=0}
          signal VehIdNmDig2_9__VIN_Digits_2_to_9_HS__CAN00: start 7, 64 bit, big-endian, data-type=DT_VehIdNmDig2_9, init-value=C_VehIdNmDig2_9, transfer-property=PENDING, to AFS_HS  # Desc: 8 ASCII Characters
      frame Wheel_Pulses_HS__CAN00: id 0x500, to AFS_HS, frame-length=4, can-addressing-mode=STANDARD
        pdu Wheel_Pulses_HS__CAN00: length=32, cyclic-timing={repeating-time=1, starting-time=0}, minimum-delay=0, transmission-mode-false-timing=cyclic-timing={repeating-time=1, starting-time=0}
          signal WhlPlsPerRevDrvn__Wheel_Pulses_HS__CAN00: start 6, 7 bit, big-endian, data-type=DT_WhlPlsPerRevDrvn, init-value=C_WhlPlsPerRevDrvn, transfer-property=PENDING, to AFS_HS
          signal WhlPlsPerRevNonDrvn__Wheel_Pulses_HS__CAN00: start 14, 7 bit, big-endian, data-type=DT_WhlPlsPerRevNonDrvn, init-value=C_WhlPlsPerRevNonDrvn, transfer-property=PENDING, to AFS_HS
      pdu triggering PT_USDT_Req_to_AFS_HS: pdu=USDT_Req_to_AFS_HS__CAN00, to AFS_HS
      pdu triggering PT_USDT_Req_to_All_HS_ECUs: pdu=USDT_Req_to_All_HS_ECUs__CAN00, to AFS_HS
      pdu triggering PT_USDT_Resp_From_AFS_HS: pdu=USDT_Resp_From_AFS_HS__CAN00, from AFS_HS
      tp-channels:
        addressing-format=STANDARD, data-pdu=USDT_Req_to_All_HS_ECUs_Tp__CAN00, multicast-addressing=true, padding-activation=true, tp-sdu=USDT_Req_to_All_HS_ECUs__CAN00
        addressing-format=STANDARD, data-pdu=USDT_Req_to_All_HS_ECUs_Tp__CAN00, multicast-addressing=true, padding-activation=true, tp-sdu=USDT_Req_to_All_HS_ECUs__CAN00
        addressing-format=STANDARD, data-pdu=USDT_Resp_From_AFS_HS_Tp__CAN00, flow-control-pdu=USDT_Req_to_AFS_HS_Tp__CAN00, multicast-addressing=false, padding-activation=true, source=CN_CAN00, tp-sdu=USDT_Resp_From_AFS_HS__CAN00
        addressing-format=STANDARD, data-pdu=USDT_Resp_From_AFS_HS_Tp__CAN00, flow-control-pdu=USDT_Req_to_AFS_HS_Tp__CAN00, multicast-addressing=false, padding-activation=true, source=CN_CAN00, tp-sdu=USDT_Resp_From_AFS_HS__CAN00
        addressing-format=STANDARD, data-pdu=USDT_Req_to_AFS_HS_Tp__CAN00, flow-control-pdu=USDT_Resp_From_AFS_HS_Tp__CAN00, multicast-addressing=false, padding-activation=true, target=CN_CAN00, tp-sdu=USDT_Req_to_AFS_HS__CAN00
        addressing-format=STANDARD, data-pdu=USDT_Req_to_AFS_HS_Tp__CAN00, flow-control-pdu=USDT_Resp_From_AFS_HS_Tp__CAN00, multicast-addressing=false, padding-activation=true, target=CN_CAN00, tp-sdu=USDT_Req_to_AFS_HS__CAN00
package /ECU
  ecu instance AFS_HS: associated-i-pdu-group=[AFS_HS__CAN00_Rx, AFS_HS__CAN00_Tx], com-processing-period=0.001  # Active Front Steering
    can communication controller CT_CAN00
    communication connector CN_CAN00: channel=CHNL, comm-controller=CT_CAN00
package /IPDUGroup
  i pdu group AFS_HS__CAN00_Rx: communication-direction=IN, i-pdu=[Antilock_Brake_and_TC_Status_HS__CAN00, Driven_Wheel_Grnd_Velocity_HS__CAN00, Driving_Mode_Control_HS__CAN00, NonDriven_Wheel_Grnd_Velocity_HS__CAN00, PPEI_Chassis_General_Status_1__CAN00, PPEI_Driven_Whl_Rotational_Stat__CAN00, PPEI_Engine_General_Status_1__CAN00, PPEI_Engine_General_Status_3__CAN00, PPEI_NonDrivn_Whl_Rotationl_Stat__CAN00, PPEI_Platform_General_Status__CAN00, PPEI_Trans_General_Status_2__CAN00, PPEI_VIN_Digits_10_to_17__CAN00, Vehicle_Odometer_HS__CAN00, VIN_Digits_2_to_9_HS__CAN00, Wheel_Pulses_HS__CAN00]
  i pdu group AFS_HS__CAN00_Tx: communication-direction=OUT, i-pdu=[AFS_Status_HS__CAN00, DTC_Triggered_779__CAN00]
package /PDU
  dcm i pdu USDT_Req_to_AFS_HS__CAN00: length=64
  dcm i pdu USDT_Req_to_All_HS_ECUs__CAN00: length=64
  dcm i pdu USDT_Resp_From_AFS_HS__CAN00: length=64
package /DataType
  42 x boolean type:
    DT_ABSAtv: compu {0=Cx0_false, 1=Cx1_true}
    DT_ABSFld: compu {0=Cx0_false, 1=Cx1_true}
    DT_AccActPosV: compu {0=Cx0_Valid, 1=Cx1_Invalid}
    DT_AFSIndOn: compu {0=Cx0_false, 1=Cx1_true}
    DT_AFSSysFail: compu {0=Cx0_false, 1=Cx1_true}
    DT_DTCI_CodeSupported_779: compu {0=Cx0_false, 1=Cx1_true}
    DT_DTCI_CurrentStatus_779: compu {0=Cx0_false, 1=Cx1_true}
    DT_DTCI_DTCTriggered_779: compu {0=Cx0_false, 1=Cx1_true}
    DT_DTCI_HistStat_779: compu {0=Cx0_false, 1=Cx1_true}
    DT_DTCI_TstFldCdClrdStat_779: compu {0=Cx0_false, 1=Cx1_true}
    DT_DTCI_TstFldPwrUpSt_779: compu {0=Cx0_false, 1=Cx1_true}
    DT_DTCI_TstNPsdCdClrdSt_779: compu {0=Cx0_false, 1=Cx1_true}
    DT_DTCI_TstNPsdPwrUpSt_779: compu {0=Cx0_false, 1=Cx1_true}
    DT_DTCI_WrnIndRqdSt_779: compu {0=Cx0_false, 1=Cx1_true}
    DT_DTCIUnused{1..7}_779: compu {0=Cx0_false, 1=Cx1_true}
    DT_EngRunAtv: compu {0=Cx0_false, 1=Cx1_true}
    DT_FrStSysVeTpSpLimIndOn: compu {0=Cx0_false, 1=Cx1_true}
    DT_GenFld: compu {0=Cx0_false, 1=Cx1_true}
    DT_SIRDpl: compu {0=Cx0_false, 1=Cx1_true}
    DT_SysBkupPwrMdEn: compu {0=Cx0_false, 1=Cx1_true}
    DT_TransEstGearV: compu {0=Cx0_Valid, 1=Cx1_Invalid}
    DT_TrnsEngdStateV: compu {0=Cx0_Valid, 1=Cx1_Invalid}
    DT_TrStLgMdAtv: compu {0=Cx0_false, 1=Cx1_true}
    DT_VehOdoV: compu {0=Cx0_Valid, 1=Cx1_Invalid}
    DT_WhlGrndVlctyLftDrvnV: compu {0=Cx0_Valid, 1=Cx1_Invalid}
    DT_WhlGrndVlctyLftNnDrvnV: compu {0=Cx0_Valid, 1=Cx1_Invalid}
    DT_WhlGrndVlctyRtDrvnV: compu {0=Cx0_Valid, 1=Cx1_Invalid}
    DT_WhlGrndVlctyRtNnDrvnV: compu {0=Cx0_Valid, 1=Cx1_Invalid}
    DT_WRSLDWhlDistVal: compu {0=Cx0_Valid, 1=Cx1_Invalid}
    DT_WRSLDWhlRotStatRst: compu {0=Cx0_false, 1=Cx1_true}
    DT_WRSLNDWhlDistVal: compu {0=Cx0_Valid, 1=Cx1_Invalid}
    DT_WRSLNDWhlRotStRst: compu {0=Cx0_false, 1=Cx1_true}
    DT_WRSRDWhlDistVal: compu {0=Cx0_Valid, 1=Cx1_Invalid}
    DT_WRSRDWhlRotStatRst: compu {0=Cx0_false, 1=Cx1_true}
    DT_WRSRNDWhlDistVal: compu {0=Cx0_Valid, 1=Cx1_Invalid}
    DT_WRSRNDWhlRotStRst: compu {0=Cx0_false, 1=Cx1_true}
  37 x integer type, all with lower-limit=0:
    DT_AccActPos: compu {phys=raw*0.392157; unit %}, upper-limit=255
    DT_DrvMdCntrlState: upper-limit=255
    DT_DTCI_DTCFailType_779: upper-limit=255
    DT_DTCI_DTCFaultType_779: compu {0=Cx00_Not_Supported (Not Supported), 1=Cx01_Type_A (Type A), 2=Cx02_Type_B (Type B), 3=Cx03_Type_C (Type C)}, upper-limit=255
    DT_DTCI_DTCNumber_779: upper-limit=65535
    DT_DTCI_DTCSource_779: upper-limit=255
    DT_EngSpd: compu {phys=raw*0.25; unit rpm}, upper-limit=65535
    DT_StSysVehTopSpdLimReq: compu {phys=raw*2; unit km/h}, upper-limit=255
    DT_SysBkUpPwrMd: compu {0=Cx0_Off, 1=Cx1_Accessory, 2=Cx2_Run, 3=Cx3_Crank_Request (Crank Request)}, upper-limit=3
    DT_SysPwrMd: compu {0=Cx0_Off, 1=Cx1_Accessory, 2=Cx2_Run, 3=Cx3_Crank_Request (Crank Request)}, upper-limit=3
    DT_TransEstGear: compu {0=Cx0_Not_Supported (Not Supported), 1=Cx1_First_Gear (First Gear), 2=Cx2_Second_Gear (Second Gear), 3=Cx3_Third_Gear (Third Gear), 4=Cx4_Fourth_Gear (Fourth Gear), 5=Cx5_Fifth_Gear (Fifth Gear), 6=Cx6_Sixth_Gear (Sixth Gear), 7=Cx7_Seventh_Gear (Seventh Gear), 8=Cx8_Eighth_Gear (Eighth Gear), 12=CxC_CVT_Forward_Gear (CVT Forward Gear), 13=CxD_Neutral_Gear (Neutral Gear), 14=CxE_Reverse_Gear (Reverse Gear), 15=CxF_Park_Gear (Park Gear)}, upper-limit=15
    DT_TrnsEngdState: compu {0=Cx0_Transmission_Not_Engaged (Transmission Not Engaged), 1=Cx1_Transmission_Engaged_in_Forward (Transmission Engaged in Forward), 2=Cx2_Transmission_Engaged_in_Reverse (Transmission Engaged in Reverse), 3=Cx3_Operating_State_Not_Reached (Operating State Not Reached)}, upper-limit=3
    DT_VehOdo: compu {phys=raw/64; unit km}, upper-limit=4294967295
    DT_VehStabEnhmntStat: compu {0=Cx0_Inactive, 1=Cx1_Active, 2=Cx2_Fault, 3=Cx3_Warming_Up (Warming Up), 4=Cx4_Not_Ready (Not Ready)}, upper-limit=7
    DT_VhDynCntlSysSt: compu {0=Cx0_Normal_Operation (Normal Operation), 1=Cx1_Reduced_Function (Reduced Function), 2=Cx2_Temporarily_Inhibited (Temporarily Inhibited), 3=Cx3_Permanently_Failed (Permanently Failed), 4=Cx4_Warming_Up (Warming Up), 5=Cx5_Calibrating, 6=Cx6_Enhanced_Operation (Enhanced Operation), 7=Cx7_Driver_Disabled (Driver Disabled)}, upper-limit=7
    DT_WhlGrndVlctyLftDrvn: compu {phys=raw/32; unit km / h}, upper-limit=16383
    DT_WhlGrndVlctyLftNnDrvn: compu {phys=raw/32; unit km / h}, upper-limit=16383
    DT_WhlGrndVlctyRtDrvn: compu {phys=raw/32; unit km / h}, upper-limit=16383
    DT_WhlGrndVlctyRtNnDrvn: compu {phys=raw/32; unit km / h}, upper-limit=16383
    DT_WhlPlsPerRevDrvn: upper-limit=127
    DT_WhlPlsPerRevNonDrvn: upper-limit=127
    DT_WRSLDSeqNum: compu {; unit counts}, upper-limit=3
    DT_WRSLDWhlDistPlsCntr: compu {; unit counts}, upper-limit=1023
    DT_WRSLDWhlDisTpRC: compu {; unit counts}, upper-limit=3
    DT_WRSLDWhlDistTmstm: compu {; unit counts}, upper-limit=65535
    DT_WRSLNDSeqNum: compu {; unit counts}, upper-limit=3
    DT_WRSLNDWhlDistPCntr: compu {; unit counts}, upper-limit=1023
    DT_WRSLNDWhlDisTpRC: compu {; unit counts}, upper-limit=3
    DT_WRSLNDWhlDistTstm: compu {; unit counts}, upper-limit=65535
    DT_WRSRDSeqNum: compu {; unit counts}, upper-limit=3
    DT_WRSRDWhlDistPlsCntr: compu {; unit counts}, upper-limit=1023
    DT_WRSRDWhlDisTpRC: compu {; unit counts}, upper-limit=3
    DT_WRSRDWhlDistTmstm: compu {; unit counts}, upper-limit=65535
    DT_WRSRNDSeqNum: compu {; unit counts}, upper-limit=3
    DT_WRSRNDWhlDistPCntr: compu {; unit counts}, upper-limit=1023
    DT_WRSRNDWhlDisTpRC: compu {; unit counts}, upper-limit=3
    DT_WRSRNDWhlDistTstm: compu {; unit counts}, upper-limit=65535
  string type DT_VehIdNmDig10_17: encoding=ISO-8859-1, max-number-of-chars=8
  string type DT_VehIdNmDig2_9: encoding=ISO-8859-1, max-number-of-chars=8
package /DataType/Unit
  6 x unit:
    U_counts: display-name=counts
    U_km: display-name=km
    U_km___h: display-name=km / h
    U_km_h: display-name=km/h
    U_p: display-name=%
    U_rpm: display-name=rpm
package /Constant
  81 x constant specification:
    C_ABSAtv
      value:
        boolean literal C_ABSAtv: type=DT_ABSAtv, value=false
    C_ABSFld
      value:
        boolean literal C_ABSFld: type=DT_ABSFld, value=false
    C_AccActPosV
      value:
        boolean literal C_AccActPosV: type=DT_AccActPosV, value=false
    C_AFSIndOn
      value:
        boolean literal C_AFSIndOn: type=DT_AFSIndOn, value=false
    C_AFSSysFail
      value:
        boolean literal C_AFSSysFail: type=DT_AFSSysFail, value=false
    C_DTCI_CodeSupported_779
      value:
        boolean literal C_DTCI_CodeSupported_779: type=DT_DTCI_CodeSupported_779, value=false
    C_DTCI_CurrentStatus_779
      value:
        boolean literal C_DTCI_CurrentStatus_779: type=DT_DTCI_CurrentStatus_779, value=false
    C_DTCI_DTCTriggered_779
      value:
        boolean literal C_DTCI_DTCTriggered_779: type=DT_DTCI_DTCTriggered_779, value=false
    C_DTCI_HistStat_779
      value:
        boolean literal C_DTCI_HistStat_779: type=DT_DTCI_HistStat_779, value=false
    C_DTCI_TstFldCdClrdStat_779
      value:
        boolean literal C_DTCI_TstFldCdClrdStat_779: type=DT_DTCI_TstFldCdClrdStat_779, value=false
    C_DTCI_TstFldPwrUpSt_779
      value:
        boolean literal C_DTCI_TstFldPwrUpSt_779: type=DT_DTCI_TstFldPwrUpSt_779, value=false
    C_DTCI_TstNPsdCdClrdSt_779
      value:
        boolean literal C_DTCI_TstNPsdCdClrdSt_779: type=DT_DTCI_TstNPsdCdClrdSt_779, value=false
    C_DTCI_TstNPsdPwrUpSt_779
      value:
        boolean literal C_DTCI_TstNPsdPwrUpSt_779: type=DT_DTCI_TstNPsdPwrUpSt_779, value=false
    C_DTCI_WrnIndRqdSt_779
      value:
        boolean literal C_DTCI_WrnIndRqdSt_779: type=DT_DTCI_WrnIndRqdSt_779, value=false
    C_DTCIUnused1_779
      value:
        boolean literal C_DTCIUnused1_779: type=DT_DTCIUnused1_779, value=false
    C_DTCIUnused2_779
      value:
        boolean literal C_DTCIUnused2_779: type=DT_DTCIUnused2_779, value=false
    C_DTCIUnused3_779
      value:
        boolean literal C_DTCIUnused3_779: type=DT_DTCIUnused3_779, value=false
    C_DTCIUnused4_779
      value:
        boolean literal C_DTCIUnused4_779: type=DT_DTCIUnused4_779, value=false
    C_DTCIUnused5_779
      value:
        boolean literal C_DTCIUnused5_779: type=DT_DTCIUnused5_779, value=false
    C_DTCIUnused6_779
      value:
        boolean literal C_DTCIUnused6_779: type=DT_DTCIUnused6_779, value=false
    C_DTCIUnused7_779
      value:
        boolean literal C_DTCIUnused7_779: type=DT_DTCIUnused7_779, value=false
    C_EngRunAtv
      value:
        boolean literal C_EngRunAtv: type=DT_EngRunAtv, value=false
    C_FrStSysVeTpSpLimIndOn
      value:
        boolean literal C_FrStSysVeTpSpLimIndOn: type=DT_FrStSysVeTpSpLimIndOn, value=false
    C_GenFld
      value:
        boolean literal C_GenFld: type=DT_GenFld, value=false
    C_SIRDpl
      value:
        boolean literal C_SIRDpl: type=DT_SIRDpl, value=false
    C_SysBkupPwrMdEn
      value:
        boolean literal C_SysBkupPwrMdEn: type=DT_SysBkupPwrMdEn, value=false
    C_TransEstGearV
      value:
        boolean literal C_TransEstGearV: type=DT_TransEstGearV, value=false
    C_TrnsEngdStateV
      value:
        boolean literal C_TrnsEngdStateV: type=DT_TrnsEngdStateV, value=false
    C_TrStLgMdAtv
      value:
        boolean literal C_TrStLgMdAtv: type=DT_TrStLgMdAtv, value=false
    C_VehOdoV
      value:
        boolean literal C_VehOdoV: type=DT_VehOdoV, value=false
    C_WhlGrndVlctyLftDrvnV
      value:
        boolean literal C_WhlGrndVlctyLftDrvnV: type=DT_WhlGrndVlctyLftDrvnV, value=false
    C_WhlGrndVlctyLftNnDrvnV
      value:
        boolean literal C_WhlGrndVlctyLftNnDrvnV: type=DT_WhlGrndVlctyLftNnDrvnV, value=false
    C_WhlGrndVlctyRtDrvnV
      value:
        boolean literal C_WhlGrndVlctyRtDrvnV: type=DT_WhlGrndVlctyRtDrvnV, value=false
    C_WhlGrndVlctyRtNnDrvnV
      value:
        boolean literal C_WhlGrndVlctyRtNnDrvnV: type=DT_WhlGrndVlctyRtNnDrvnV, value=false
    C_WRSLDWhlDistVal
      value:
        boolean literal C_WRSLDWhlDistVal: type=DT_WRSLDWhlDistVal, value=false
    C_WRSLDWhlRotStatRst
      value:
        boolean literal C_WRSLDWhlRotStatRst: type=DT_WRSLDWhlRotStatRst, value=false
    C_WRSLNDWhlDistVal
      value:
        boolean literal C_WRSLNDWhlDistVal: type=DT_WRSLNDWhlDistVal, value=false
    C_WRSLNDWhlRotStRst
      value:
        boolean literal C_WRSLNDWhlRotStRst: type=DT_WRSLNDWhlRotStRst, value=false
    C_WRSRDWhlDistVal
      value:
        boolean literal C_WRSRDWhlDistVal: type=DT_WRSRDWhlDistVal, value=false
    C_WRSRDWhlRotStatRst
      value:
        boolean literal C_WRSRDWhlRotStatRst: type=DT_WRSRDWhlRotStatRst, value=false
    C_WRSRNDWhlDistVal
      value:
        boolean literal C_WRSRNDWhlDistVal: type=DT_WRSRNDWhlDistVal, value=false
    C_WRSRNDWhlRotStRst
      value:
        boolean literal C_WRSRNDWhlRotStRst: type=DT_WRSRNDWhlRotStRst, value=false
    C_AccActPos
      value:
        integer literal C_AccActPos: type=DT_AccActPos, value=0
    C_DrvMdCntrlState
      value:
        integer literal C_DrvMdCntrlState: type=DT_DrvMdCntrlState, value=0
    C_DTCI_DTCFailType_779
      value:
        integer literal C_DTCI_DTCFailType_779: type=DT_DTCI_DTCFailType_779, value=0
    C_DTCI_DTCFaultType_779
      value:
        integer literal C_DTCI_DTCFaultType_779: type=DT_DTCI_DTCFaultType_779, value=0
    C_DTCI_DTCNumber_779
      value:
        integer literal C_DTCI_DTCNumber_779: type=DT_DTCI_DTCNumber_779, value=0
    C_DTCI_DTCSource_779
      value:
        integer literal C_DTCI_DTCSource_779: type=DT_DTCI_DTCSource_779, value=0
    C_EngSpd
      value:
        integer literal C_EngSpd: type=DT_EngSpd, value=0
    C_StSysVehTopSpdLimReq
      value:
        integer literal C_StSysVehTopSpdLimReq: type=DT_StSysVehTopSpdLimReq, value=0
    C_SysBkUpPwrMd
      value:
        integer literal C_SysBkUpPwrMd: type=DT_SysBkUpPwrMd, value=0
    C_SysPwrMd
      value:
        integer literal C_SysPwrMd: type=DT_SysPwrMd, value=0
    C_TransEstGear
      value:
        integer literal C_TransEstGear: type=DT_TransEstGear, value=15
    C_TrnsEngdState
      value:
        integer literal C_TrnsEngdState: type=DT_TrnsEngdState, value=0
    C_VehOdo
      value:
        integer literal C_VehOdo: type=DT_VehOdo, value=0
    C_VehStabEnhmntStat
      value:
        integer literal C_VehStabEnhmntStat: type=DT_VehStabEnhmntStat, value=0
    C_VhDynCntlSysSt
      value:
        integer literal C_VhDynCntlSysSt: type=DT_VhDynCntlSysSt, value=0
    C_WhlGrndVlctyLftDrvn
      value:
        integer literal C_WhlGrndVlctyLftDrvn: type=DT_WhlGrndVlctyLftDrvn, value=0
    C_WhlGrndVlctyLftNnDrvn
      value:
        integer literal C_WhlGrndVlctyLftNnDrvn: type=DT_WhlGrndVlctyLftNnDrvn, value=0
    C_WhlGrndVlctyRtDrvn
      value:
        integer literal C_WhlGrndVlctyRtDrvn: type=DT_WhlGrndVlctyRtDrvn, value=0
    C_WhlGrndVlctyRtNnDrvn
      value:
        integer literal C_WhlGrndVlctyRtNnDrvn: type=DT_WhlGrndVlctyRtNnDrvn, value=0
    C_WhlPlsPerRevDrvn
      value:
        integer literal C_WhlPlsPerRevDrvn: type=DT_WhlPlsPerRevDrvn, value=0
    C_WhlPlsPerRevNonDrvn
      value:
        integer literal C_WhlPlsPerRevNonDrvn: type=DT_WhlPlsPerRevNonDrvn, value=0
    C_WRSLDSeqNum
      value:
        integer literal C_WRSLDSeqNum: type=DT_WRSLDSeqNum, value=0
    C_WRSLDWhlDistPlsCntr
      value:
        integer literal C_WRSLDWhlDistPlsCntr: type=DT_WRSLDWhlDistPlsCntr, value=0
    C_WRSLDWhlDisTpRC
      value:
        integer literal C_WRSLDWhlDisTpRC: type=DT_WRSLDWhlDisTpRC, value=0
    C_WRSLDWhlDistTmstm
      value:
        integer literal C_WRSLDWhlDistTmstm: type=DT_WRSLDWhlDistTmstm, value=0
    C_WRSLNDSeqNum
      value:
        integer literal C_WRSLNDSeqNum: type=DT_WRSLNDSeqNum, value=0
    C_WRSLNDWhlDistPCntr
      value:
        integer literal C_WRSLNDWhlDistPCntr: type=DT_WRSLNDWhlDistPCntr, value=0
    C_WRSLNDWhlDisTpRC
      value:
        integer literal C_WRSLNDWhlDisTpRC: type=DT_WRSLNDWhlDisTpRC, value=0
    C_WRSLNDWhlDistTstm
      value:
        integer literal C_WRSLNDWhlDistTstm: type=DT_WRSLNDWhlDistTstm, value=0
    C_WRSRDSeqNum
      value:
        integer literal C_WRSRDSeqNum: type=DT_WRSRDSeqNum, value=0
    C_WRSRDWhlDistPlsCntr
      value:
        integer literal C_WRSRDWhlDistPlsCntr: type=DT_WRSRDWhlDistPlsCntr, value=0
    C_WRSRDWhlDisTpRC
      value:
        integer literal C_WRSRDWhlDisTpRC: type=DT_WRSRDWhlDisTpRC, value=0
    C_WRSRDWhlDistTmstm
      value:
        integer literal C_WRSRDWhlDistTmstm: type=DT_WRSRDWhlDistTmstm, value=0
    C_WRSRNDSeqNum
      value:
        integer literal C_WRSRNDSeqNum: type=DT_WRSRNDSeqNum, value=0
    C_WRSRNDWhlDistPCntr
      value:
        integer literal C_WRSRNDWhlDistPCntr: type=DT_WRSRNDWhlDistPCntr, value=0
    C_WRSRNDWhlDisTpRC
      value:
        integer literal C_WRSRNDWhlDisTpRC: type=DT_WRSRNDWhlDisTpRC, value=0
    C_WRSRNDWhlDistTstm
      value:
        integer literal C_WRSRNDWhlDistTstm: type=DT_WRSRNDWhlDistTstm, value=0
    C_VehIdNmDig10_17
      value:
        string literal C_VehIdNmDig10_17: type=DT_VehIdNmDig10_17
    C_VehIdNmDig2_9
      value:
        string literal C_VehIdNmDig2_9: type=DT_VehIdNmDig2_9
